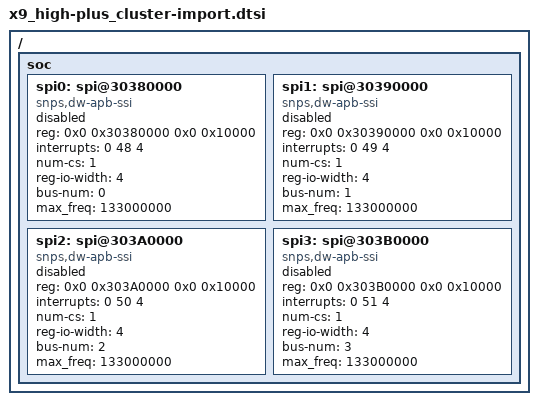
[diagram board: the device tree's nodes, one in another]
/*
* Semidrive X9 platform DTS file
*
* Copyright (C) 2019, Semidrive  Communications Inc.
*
* This file is licensed under a dual GPLv2 or X11 license.
*/

/*Note: add safety/rtc imported resources here!*/

/ {
	soc{

		spi0: spi@30380000 { /* physical spi num is 1 */
			compatible = "snps,dw-apb-ssi";
			reg = <0x0 0x30380000 0x0 0x10000>;
			interrupts = <0 48 4>;
			num-cs = <1>;
			reg-io-width = <4>;
			bus-num = <0>;
			#address-cells = <1>;
			#size-cells = <0>;
			max_freq = <133000000>;
			status = "disabled";
		};

		spi1: spi@30390000 { /* physical spi num is 2 */
			compatible = "snps,dw-apb-ssi";
			reg = <0x0 0x30390000 0x0 0x10000>;
			interrupts = <0 49 4>;
			num-cs = <1>;
			reg-io-width = <4>;
			bus-num = <1>;
			#address-cells = <1>;
			#size-cells = <0>;
			max_freq = <133000000>;
			status = "disabled";
		};

		spi2: spi@303A0000 { /* physical spi num is 3 */
			compatible = "snps,dw-apb-ssi";
			reg = <0x0 0x303A0000 0x0 0x10000>;
			interrupts = <0 50 4>;
			num-cs = <1>;
			reg-io-width = <4>;
			bus-num = <2>;
			#address-cells = <1>;
			#size-cells = <0>;
			max_freq = <133000000>;
			status = "disabled";
		};

		spi3: spi@303B0000 { /* physical spi num is 4 */
			compatible = "snps,dw-apb-ssi";
			reg = <0x0 0x303B0000 0x0 0x10000>;
			interrupts = <0 51 4>;
			num-cs = <1>;
			reg-io-width = <4>;
			bus-num = <3>;
			#address-cells = <1>;
			#size-cells = <0>;
			max_freq = <133000000>;
			status = "disabled";
		};
	};
};
